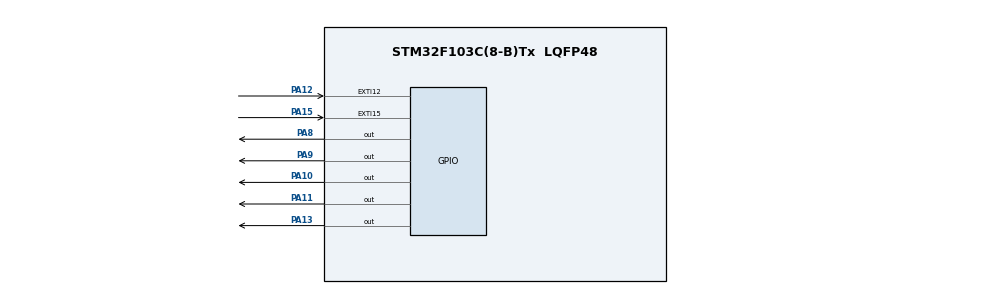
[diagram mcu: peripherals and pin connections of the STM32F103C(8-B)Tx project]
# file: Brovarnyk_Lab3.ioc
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Mcu.Family=STM32F1
Mcu.Name=STM32F103C(8-B)Tx
Mcu.Package=LQFP48
NVIC.EXTI15_10_IRQn=true\:0\:0\:false\:true\:true\:1\:true\:true
NVIC.PriorityGroup=NVIC_PRIORITYGROUP_4
PA10.Signal=GPIO_Output
PA11.Signal=GPIO_Output
PA12.Signal=GPXTI12
PA13.Signal=GPIO_Output
PA15.Signal=GPXTI15
PA8.Signal=GPIO_Output
PA9.Signal=GPIO_Output
ProjectManager.HeapSize=0x200
ProjectManager.StackSize=0x400
ProjectManager.TargetToolchain=STM32CubeIDE
RCC.APB1Freq_Value=8000000
RCC.APB2Freq_Value=8000000
VP_SYS_VS_ND.Mode=No_Debug
board=custom

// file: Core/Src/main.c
/* USER CODE BEGIN Header */
/**
  ******************************************************************************
  * @file           : main.c
  * @brief          : Main program body
  ******************************************************************************
  * @attention
  *
  * Copyright (c) 2022 STMicroelectronics.
  * All rights reserved.
  *
  * This software is licensed under terms that can be found in the LICENSE file
  * in the root directory of this software component.
  * If no LICENSE file comes with this software, it is provided AS-IS.
  *
  ******************************************************************************
  */
/* USER CODE END Header */
#include "main.h"

void SystemClock_Config(void);
static void MX_GPIO_Init(void);
static void MX_NVIC_Init(void);

int main(void)
{

  /* MCU Configuration--------------------------------------------------------*/

  /* Reset of all peripherals, Initializes the Flash interface and the Systick. */
  HAL_Init();

  /* Configure the system clock */
  SystemClock_Config();

  /* Initialize all configured peripherals */
  MX_GPIO_Init();

  /* Initialize interrupts */
  MX_NVIC_Init();
  /* USER CODE BEGIN 2 */
  HAL_GPIO_WritePin(GPIOA, GPIO_PIN_8, GPIO_PIN_SET);
  HAL_GPIO_WritePin(GPIOA, GPIO_PIN_9, GPIO_PIN_SET);
  HAL_GPIO_WritePin(GPIOA, GPIO_PIN_10, GPIO_PIN_SET);
  HAL_GPIO_WritePin(GPIOA, GPIO_PIN_11, GPIO_PIN_SET);
  /* USER CODE END 2 */

  /* Infinite loop */
  while (1)
  {

  }
}

void SystemClock_Config(void)
{
  RCC_OscInitTypeDef RCC_OscInitStruct = {0};
  RCC_ClkInitTypeDef RCC_ClkInitStruct = {0};

  /** Initializes the RCC Oscillators according to the specified parameters
  * in the RCC_OscInitTypeDef structure.
  */
  RCC_OscInitStruct.OscillatorType = RCC_OSCILLATORTYPE_HSI;
  RCC_OscInitStruct.HSIState = RCC_HSI_ON;
  RCC_OscInitStruct.HSICalibrationValue = RCC_HSICALIBRATION_DEFAULT;
  RCC_OscInitStruct.PLL.PLLState = RCC_PLL_NONE;
  if (HAL_RCC_OscConfig(&RCC_OscInitStruct) != HAL_OK)
  {
    Error_Handler();
  }
  /** Initializes the CPU, AHB and APB buses clocks
  */
  RCC_ClkInitStruct.ClockType = RCC_CLOCKTYPE_HCLK|RCC_CLOCKTYPE_SYSCLK
                              |RCC_CLOCKTYPE_PCLK1|RCC_CLOCKTYPE_PCLK2;
  RCC_ClkInitStruct.SYSCLKSource = RCC_SYSCLKSOURCE_HSI;
  RCC_ClkInitStruct.AHBCLKDivider = RCC_SYSCLK_DIV1;
  RCC_ClkInitStruct.APB1CLKDivider = RCC_HCLK_DIV1;
  RCC_ClkInitStruct.APB2CLKDivider = RCC_HCLK_DIV1;

  if (HAL_RCC_ClockConfig(&RCC_ClkInitStruct, FLASH_LATENCY_0) != HAL_OK)
  {
    Error_Handler();
  }
}

/**
  * @brief NVIC Configuration.
  * @retval None
  */
static void MX_NVIC_Init(void)
{
  /* EXTI15_10_IRQn interrupt configuration */
  HAL_NVIC_SetPriority(EXTI15_10_IRQn, 0, 0);
  HAL_NVIC_EnableIRQ(EXTI15_10_IRQn);
}

static void MX_GPIO_Init(void)
{
  GPIO_InitTypeDef GPIO_InitStruct = {0};

  /* GPIO Ports Clock Enable */
  __HAL_RCC_GPIOA_CLK_ENABLE();

  /*Configure GPIO pin Output Level */
  HAL_GPIO_WritePin(GPIOA, GPIO_PIN_8|GPIO_PIN_9|GPIO_PIN_10|GPIO_PIN_11
                          |GPIO_PIN_13, GPIO_PIN_RESET);

  /*Configure GPIO pins : PA8 PA9 PA10 PA11
                           PA13 */
  GPIO_InitStruct.Pin = GPIO_PIN_8|GPIO_PIN_9|GPIO_PIN_10|GPIO_PIN_11
                          |GPIO_PIN_13;
  GPIO_InitStruct.Mode = GPIO_MODE_OUTPUT_PP;
  GPIO_InitStruct.Pull = GPIO_NOPULL;
  GPIO_InitStruct.Speed = GPIO_SPEED_FREQ_LOW;
  HAL_GPIO_Init(GPIOA, &GPIO_InitStruct);

  /*Configure GPIO pins : PA12 PA15 */
  GPIO_InitStruct.Pin = GPIO_PIN_12|GPIO_PIN_15;
  GPIO_InitStruct.Mode = GPIO_MODE_IT_RISING;
  GPIO_InitStruct.Pull = GPIO_NOPULL;
  HAL_GPIO_Init(GPIOA, &GPIO_InitStruct);

}

/* USER CODE BEGIN 4 */
int i = GPIO_PIN_8;

void HAL_GPIO_EXTI_Callback(uint16_t GPIO_Pin)
{
	if(GPIO_Pin == GPIO_PIN_15)
	{
		HAL_GPIO_WritePin(GPIOA, i, GPIO_PIN_RESET);
		if(i < GPIO_PIN_11) i = i << 1;
	}
	if(GPIO_Pin == GPIO_PIN_12)
	{
		HAL_GPIO_WritePin(GPIOA, i, GPIO_PIN_SET);
		if(i > GPIO_PIN_8) i = i >> 1;
	}

}
/* USER CODE END 4 */

void Error_Handler(void)
{
  __disable_irq();
  while (1)
  {
  }
}
